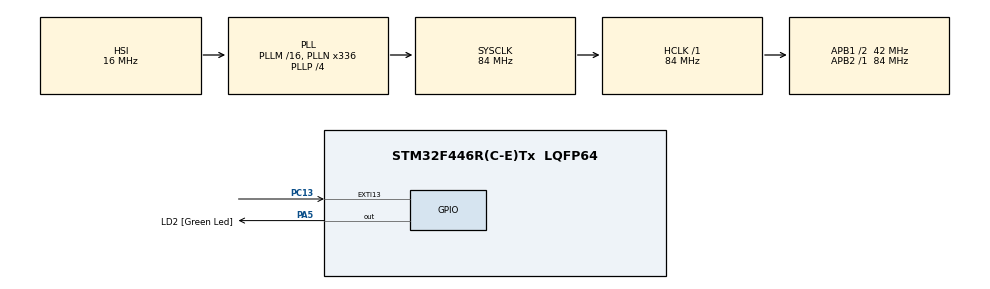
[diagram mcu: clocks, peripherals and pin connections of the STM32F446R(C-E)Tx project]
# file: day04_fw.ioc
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Mcu.Family=STM32F4
Mcu.Name=STM32F446R(C-E)Tx
Mcu.Package=LQFP64
NVIC.EXTI15_10_IRQn=true\:0\:0\:false\:false\:true\:true\:true\:true
NVIC.PriorityGroup=NVIC_PRIORITYGROUP_0
NVIC.TIM2_IRQn=true\:0\:0\:false\:false\:true\:true\:true\:true
PA13.GPIO_Label=TMS
PA13.Mode=Serial_Wire
PA13.Signal=SYS_JTMS-SWDIO
PA14.GPIO_Label=TCK
PA14.Mode=Serial_Wire
PA14.Signal=SYS_JTCK-SWCLK
PA5.GPIO_Label=LD2 [Green Led]
PA5.Signal=GPIO_Output
PB3.GPIO_Label=SWO
PB3.Signal=SYS_JTDO-SWO
PC13.GPIO_ModeDefaultEXTI=GPIO_MODE_IT_FALLING
PC13.Signal=GPXTI13
ProjectManager.HeapSize=0x200
ProjectManager.StackSize=0x400
ProjectManager.TargetToolchain=STM32CubeIDE
RCC.48MHZClocksFreq_Value=84000000
RCC.AHBFreq_Value=84000000
RCC.APB1CLKDivider=RCC_HCLK_DIV2
RCC.APB1Freq_Value=42000000
RCC.APB1TimFreq_Value=84000000
RCC.APB2Freq_Value=84000000
RCC.APB2TimFreq_Value=84000000
RCC.CortexFreq_Value=84000000
RCC.FLatency-AdvancedSettings=FLASH_LATENCY_2
RCC.HCLKFreq_Value=84000000
RCC.HSE_VALUE=8000000
RCC.HSI_VALUE=16000000
RCC.PLLN=336
RCC.PLLP=RCC_PLLP_DIV4
RCC.SYSCLKFreq_VALUE=84000000
RCC.SYSCLKSource=RCC_SYSCLKSOURCE_PLLCLK
RCC.USBFreq_Value=168000000
RCC.VCOOutputFreq_Value=336000000
TIM2.Period=1000-1
TIM2.Prescaler=84 - 1
VP_TIM2_VS_ClockSourceINT.Mode=Internal
board=NUCLEO-F446RE

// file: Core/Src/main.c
/* USER CODE BEGIN Header */
/**
  ******************************************************************************
  * @file           : main.c
  * @brief          : Main program body
  ******************************************************************************
  * @attention
  *
  * Copyright (c) 2025 STMicroelectronics.
  * All rights reserved.
  *
  * This software is licensed under terms that can be found in the LICENSE file
  * in the root directory of this software component.
  * If no LICENSE file comes with this software, it is provided AS-IS.
  *
  ******************************************************************************
  */
/* USER CODE END Header */
#include "main.h"
#include "tim.h"
#include "gpio.h"

/* USER CODE BEGIN PV */
extern TIM_HandleTypeDef htim2;

static volatile uint8_t enable_blink = 0;
static volatile uint32_t ms = 0;
static volatile uint32_t last_press = 0;

/* USER CODE END PV */

void SystemClock_Config(void);

int main(void)
{

  /* MCU Configuration--------------------------------------------------------*/

  /* Reset of all peripherals, Initializes the Flash interface and the Systick. */
  HAL_Init();

  /* Configure the system clock */
  SystemClock_Config();

  /* Initialize all configured peripherals */
  MX_GPIO_Init();
  MX_TIM2_Init();
  /* USER CODE BEGIN 2 */
  HAL_TIM_Base_Start_IT(&htim2);
  /* USER CODE END 2 */

  /* Infinite loop */
  while (1)
  {

  }
}

void SystemClock_Config(void)
{
  RCC_OscInitTypeDef RCC_OscInitStruct = {0};
  RCC_ClkInitTypeDef RCC_ClkInitStruct = {0};

  /** Configure the main internal regulator output voltage
  */
  __HAL_RCC_PWR_CLK_ENABLE();
  __HAL_PWR_VOLTAGESCALING_CONFIG(PWR_REGULATOR_VOLTAGE_SCALE3);

  /** Initializes the RCC Oscillators according to the specified parameters
  * in the RCC_OscInitTypeDef structure.
  */
  RCC_OscInitStruct.OscillatorType = RCC_OSCILLATORTYPE_HSI;
  RCC_OscInitStruct.HSIState = RCC_HSI_ON;
  RCC_OscInitStruct.HSICalibrationValue = RCC_HSICALIBRATION_DEFAULT;
  RCC_OscInitStruct.PLL.PLLState = RCC_PLL_ON;
  RCC_OscInitStruct.PLL.PLLSource = RCC_PLLSOURCE_HSI;
  RCC_OscInitStruct.PLL.PLLM = 16;
  RCC_OscInitStruct.PLL.PLLN = 336;
  RCC_OscInitStruct.PLL.PLLP = RCC_PLLP_DIV4;
  RCC_OscInitStruct.PLL.PLLQ = 2;
  RCC_OscInitStruct.PLL.PLLR = 2;
  if (HAL_RCC_OscConfig(&RCC_OscInitStruct) != HAL_OK)
  {
    Error_Handler();
  }

  /** Initializes the CPU, AHB and APB buses clocks
  */
  RCC_ClkInitStruct.ClockType = RCC_CLOCKTYPE_HCLK|RCC_CLOCKTYPE_SYSCLK
                              |RCC_CLOCKTYPE_PCLK1|RCC_CLOCKTYPE_PCLK2;
  RCC_ClkInitStruct.SYSCLKSource = RCC_SYSCLKSOURCE_PLLCLK;
  RCC_ClkInitStruct.AHBCLKDivider = RCC_SYSCLK_DIV1;
  RCC_ClkInitStruct.APB1CLKDivider = RCC_HCLK_DIV2;
  RCC_ClkInitStruct.APB2CLKDivider = RCC_HCLK_DIV1;

  if (HAL_RCC_ClockConfig(&RCC_ClkInitStruct, FLASH_LATENCY_2) != HAL_OK)
  {
    Error_Handler();
  }
}

/* USER CODE BEGIN 4 */
void HAL_TIM_PeriodElapsedCallback(TIM_HandleTypeDef* htim) {
	// Make sure we are getting this interrupt from TIM2 that we set up
	if (htim->Instance == TIM2) {
		// this interrupt triggers every 1 ms since the timer is set to 1 kHz, and we will toggle the LED every 100ms.
		// but we only want to do that if we enabled blinking through the user button.
		if (enable_blink) {
			// we want to blink the LED every 100ms, and the timer runs at 1 kHz.
			// that means that we receive an interrupt every 1ms, so we can simply count to 100 then toggle the LED.
			if (++ms >= 100) {
				// toggles the LED
				HAL_GPIO_TogglePin(LD2_GPIO_Port, LD2_Pin);
				// reset our counter so we can continue toggling in the future.
				ms = 0;
			}
		}

	}
}

void HAL_GPIO_EXTI_Callback(uint16_t GPIO_Pin) {
	// every time the blue user button is pressed, we toggle the enable blinking status.
	if (GPIO_Pin == GPIO_PIN_13) {
		// since the user button is mechanical, it may bounce and trigger multiple interrupts
		// to prevent this unwanted behavior, we will add a debounce check.
		uint32_t now = HAL_GetTick();

		// the way the debounce check works, is we want to prevent unintentional consecutive presses
		// caused by the mechanics of the button itself rather than user intent.
		// to do that, we only accept presses if the button wasn't pressed in the last 50 ms.
		// this will reject all unwanted interrupts caused by the signal bouncing.
		if ((now - last_press) > 50U) {
			enable_blink ^= 1;
		}

		last_press = now;
	}
}
/* USER CODE END 4 */

void Error_Handler(void)
{
  __disable_irq();
  while (1)
  {
  }
}
